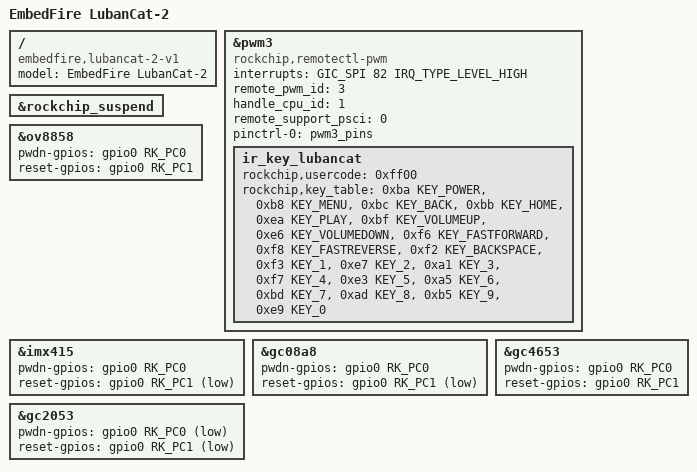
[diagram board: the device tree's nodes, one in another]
// SPDX-License-Identifier: (GPL-2.0+ OR MIT)
/*
* Copyright (c) 2020 Rockchip Electronics Co., Ltd.
*
*/

#include "rk3568-lubancat-2.dtsi"

//MIPI摄像头配置
#include "rk3568-lubancat-csi2.dtsi"

/ {
	model = "EmbedFire LubanCat-2";
	compatible = "embedfire,lubancat-2-v1", "rockchip,rk3568";
};

&pwm3 {
	status = "okay";
	
	compatible = "rockchip,remotectl-pwm";
	interrupts = <GIC_SPI 82 IRQ_TYPE_LEVEL_HIGH>;
	remote_pwm_id = <3>;
	handle_cpu_id = <1>;
	remote_support_psci = <0>;
	pinctrl-names = "default";
	pinctrl-0 = <&pwm3_pins>;
	
	ir_key_lubancat{
		rockchip,usercode = <0xff00>;
		rockchip,key_table =
		<0xba   KEY_POWER>,//电源按键
		<0xb8   KEY_MENU>,//菜单按键
		<0xbc   KEY_BACK>,//返回按键
		<0xbb   KEY_HOME>,//home键按键
		<0xea   KEY_PLAY>,//播放按键
		<0xbf   KEY_VOLUMEUP>,//音量加按键
		<0xe6   KEY_VOLUMEDOWN>,//音量键按键
		<0xf6   KEY_FASTFORWARD>,//快进按键
		<0xf8   KEY_FASTREVERSE>,//快退按键
		<0xf2   KEY_BACKSPACE>,//BaskSpace按键
		<0xf3   KEY_1>,//按键1
		<0xe7   KEY_2>,
		<0xa1   KEY_3>,
		<0xf7   KEY_4>,
		<0xe3   KEY_5>,
		<0xa5   KEY_6>,
		<0xbd   KEY_7>,
		<0xad   KEY_8>,
		<0xb5   KEY_9>,
		<0xe9   KEY_0>;//按键0
	};
};

&rockchip_suspend {
	status = "okay";
};

//cam-gpio-setting
&ov8858 {
	pwdn-gpios = <&gpio0 RK_PC0 GPIO_ACTIVE_HIGH>;
	reset-gpios = <&gpio0 RK_PC1 GPIO_ACTIVE_HIGH>;
};

&imx415 {
	pwdn-gpios = <&gpio0 RK_PC0 GPIO_ACTIVE_HIGH>;
	reset-gpios = <&gpio0 RK_PC1 GPIO_ACTIVE_LOW>; 
};

&gc08a8 {
	pwdn-gpios = <&gpio0 RK_PC0 GPIO_ACTIVE_HIGH>;
	reset-gpios = <&gpio0 RK_PC1 GPIO_ACTIVE_LOW>; 
};

&gc2053 {
	pwdn-gpios = <&gpio0 RK_PC0 GPIO_ACTIVE_LOW>;
	reset-gpios = <&gpio0 RK_PC1 GPIO_ACTIVE_LOW>; 
};

&gc4653 {
	pwdn-gpios = <&gpio0 RK_PC0 GPIO_ACTIVE_HIGH>;
	reset-gpios = <&gpio0 RK_PC1 GPIO_ACTIVE_HIGH>; 
};
